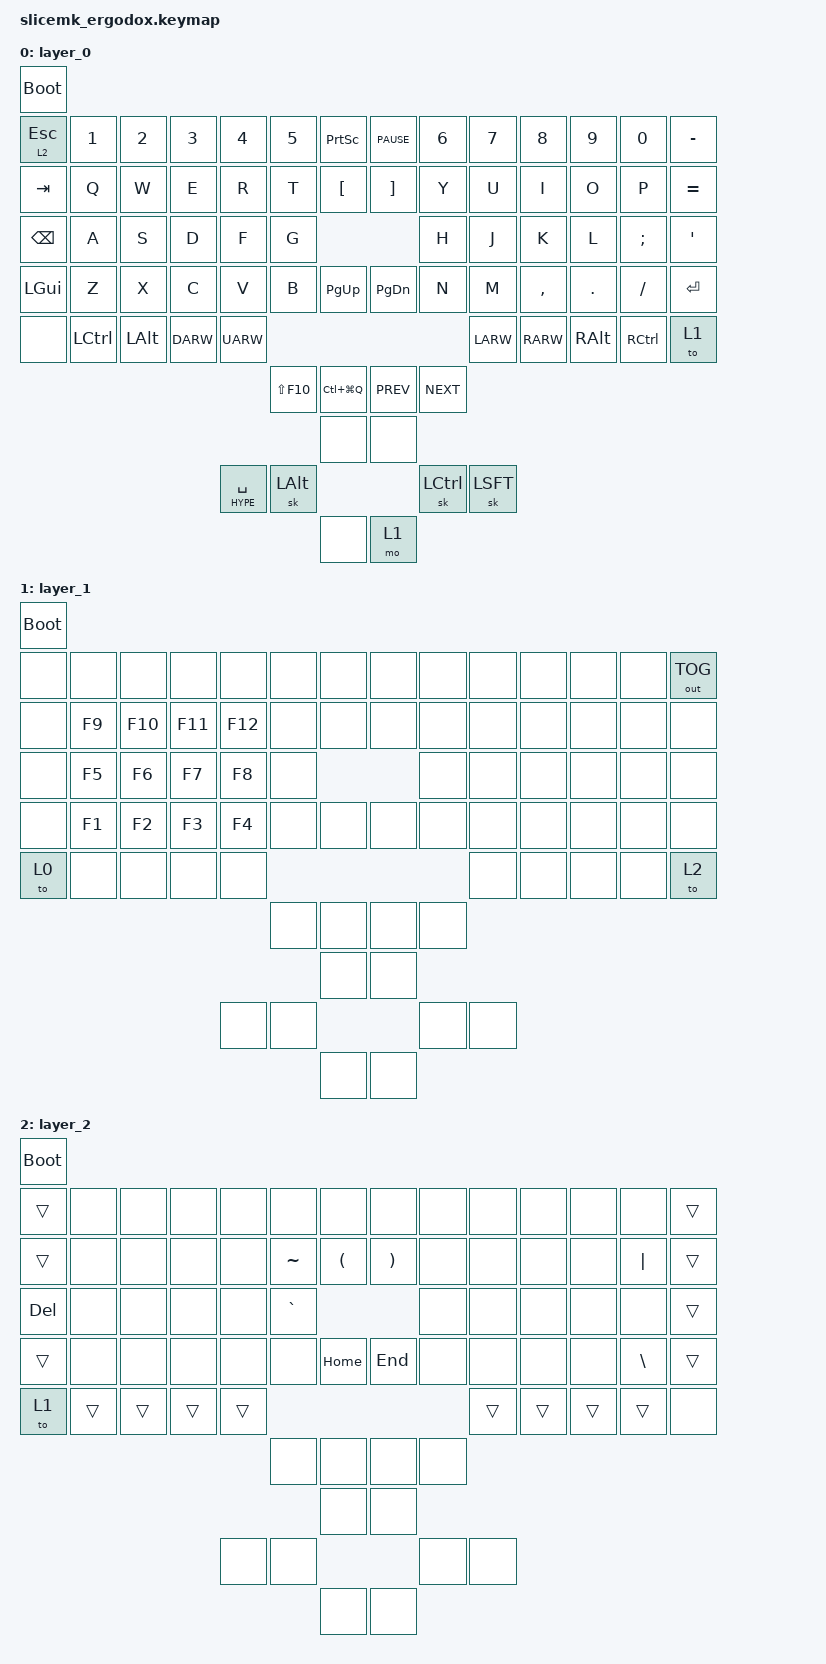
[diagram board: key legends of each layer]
#include <behaviors.dtsi>
#include <dt-bindings/zmk/bt.h>
#include <dt-bindings/zmk/keys.h>
#include <dt-bindings/zmk/outputs.h>

#define PAUSE PAUSE_BREAK
#define HYPE LG(LS(LA(LCTRL)))

&mt {
    flavor = "tap-preferred";
    tapping_term_ms = <250>;
};

&sk {
    release-after-ms = <1500>;
    quick-release;
};

/ {
        behaviors {
        };

        keymap {
                compatible = "zmk,keymap";

                layer_0 {
                        bindings = <
&bootloader
&lt 2 ESC   &kp N1    &kp N2    &kp N3     &kp N4     &kp N5     &kp PSCRN       &kp PAUSE  &kp N6     &kp N7    &kp N8    &kp N9    &kp N0     &kp MINUS
&kp TAB     &kp Q     &kp W     &kp E      &kp R      &kp T      &kp LBKT        &kp RBKT   &kp Y      &kp U     &kp I     &kp O     &kp P      &kp EQUAL
&kp BSPC    &kp A     &kp S     &kp D      &kp F      &kp G                                 &kp H      &kp J     &kp K     &kp L     &kp SEMI    &kp APOS
&kp LGUI    &kp Z     &kp X     &kp C      &kp V      &kp B      &kp PG_UP       &kp PG_DN  &kp N      &kp M     &kp CMMA  &kp DOT   &kp FSLH     &kp RET
&none       &kp LCTL  &kp LALT  &kp DARW   &kp UARW                                                    &kp LARW  &kp RARW  &kp RALT  &kp RCTL       &to 1
                                                      &kp LS(F10)&kp LC(LG(Q))   &kp C_PREV &kp C_NEXT
                                                                 &none           &none
                                         &mt HYPE SPC &sk LALT                              &sk LCTL   &sk LSFT
                                                                 &none           &mo 1
                        >;
                };

                layer_1 {
                        bindings = <
&bootloader
&none       &none     &none     &none     &none     &none      &none             &none      &none      &none     &none     &none     &none   &out OUT_TOG
&none       &kp F9    &kp F10   &kp F11   &kp F12   &none      &none             &none      &none      &none     &none     &none     &none          &none
&none       &kp F5    &kp F6    &kp F7    &kp F8    &none                                   &none      &none     &none     &none     &none          &none
&none       &kp F1    &kp F2    &kp F3    &kp F4    &none      &none             &none      &none      &none     &none     &none     &none          &none
&to 0       &none     &none     &none     &none                                                        &none     &none     &none     &none          &to 2
                                                    &none      &none             &none      &none
                                                               &none             &none
                                          &none     &none                                   &none      &none
                                                               &none             &none
                        >;
                };

                layer_2 {
                        bindings = <
&bootloader
&trans      &none     &none     &none     &none     &none      &none             &none      &none      &none     &none     &none     &none         &trans
&trans      &none     &none     &none     &none     &kp TILDE  &kp LPAR          &kp RPAR   &none      &none     &none     &none     &kp PIPE      &trans
&kp DEL     &none     &none     &none     &none     &kp GRAVE                               &none      &none     &none     &none     &none         &trans
&trans      &none     &none     &none     &none     &none      &kp HOME          &kp END    &none      &none     &none     &none     &kp BSLH      &trans
&to 1       &trans    &trans    &trans    &trans                                                       &trans    &trans    &trans    &trans         &none
                                                    &none      &none             &none      &none
                                                               &none             &none
                                          &none     &none                                   &none    &none
                                                               &none             &none
                        >;
                };
                         
        };
};
